AUTOSAR XML (schema 4-3-0)
package /MICROSAR/NvM_swc/DataTypes
  impl type NvM_BlockIdType: range raw 1..32767, implementation-data-type=uint16
  impl type NvM_RequestResultType: compu {0=NVM_REQ_OK, 1=NVM_REQ_NOT_OK, 2=NVM_REQ_PENDING, 3=NVM_REQ_INTEGRITY_FAILED, 4=NVM_REQ_BLOCK_SKIPPED, 5=NVM_REQ_NV_INVALIDATED, 6=NVM_REQ_CANCELED, 7=NVM_REQ_REDUNDANCY_FAILED, 8=NVM_REQ_RESTORED_FROM_ROM}, range raw 0..8, implementation-data-type=uint8
package /MICROSAR/NvM_swc/Interfaces
  4 x client server interface, all with is-service=true, service-kind=NON-VOLATILE-RAM-MANAGER:
    NvMAdministration
      operation SetBlockProtection: possible-error=NvMAdministration/E_NOT_OK
        arg ProtectionEnabled: type=boolean, direction=IN
      error E_NOT_OK: error-code=1
    NvMService_AC3_SRBS
      6 x operation, all with possible-error=NvMService_AC3_SRBS/E_NOT_OK:
        GetErrorStatus
          arg ErrorStatus: type=NvM_RequestResultType, direction=OUT
        SetRamBlockStatus
          arg RamBlockStatus: type=boolean, direction=IN
        ReadBlock
          arg DstPtr: type=dtRef_VOID, direction=IN
        WriteBlock
          arg SrcPtr: type=dtRef_const_VOID, direction=IN
        InvalidateNvBlock
        EraseBlock
      error E_NOT_OK: error-code=1
    NvMService_AC3_SRBS_Defs
      7 x operation, all with possible-error=NvMService_AC3_SRBS_Defs/E_NOT_OK:
        GetErrorStatus
          arg ErrorStatus: type=NvM_RequestResultType, direction=OUT
        SetRamBlockStatus
          arg RamBlockStatus: type=boolean, direction=IN
        ReadBlock
          arg DstPtr: type=dtRef_VOID, direction=IN
        WriteBlock
          arg SrcPtr: type=dtRef_const_VOID, direction=IN
        RestoreBlockDefaults
          arg DstPtr: type=dtRef_VOID, direction=IN
        InvalidateNvBlock
        EraseBlock
      error E_NOT_OK: error-code=1
    NvMNotifyInitBlock
      operation InitBlock
package /MICROSAR/NvM_swc/ComponentTypes
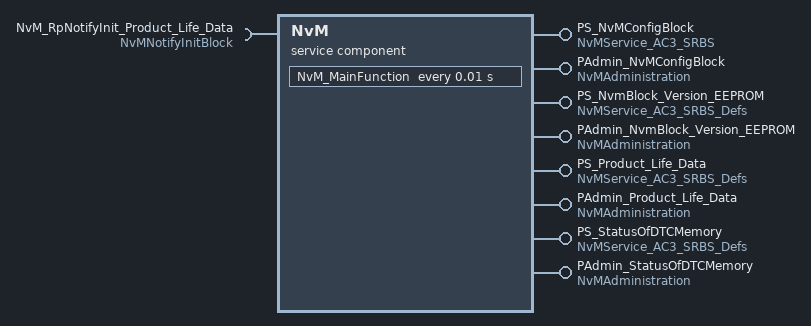
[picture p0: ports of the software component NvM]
  service sw component type NvM: category=SERVICE_COMPONENT
    6 x provide port:
      PS_NvMConfigBlock: provided-interface=NvMService_AC3_SRBS
      PAdmin_NvMConfigBlock: provided-interface=NvMAdministration
      PS_NvmBlock_Version_EEPROM: provided-interface=NvMService_AC3_SRBS_Defs
      PAdmin_NvmBlock_Version_EEPROM: provided-interface=NvMAdministration
      PS_Product_Life_Data: provided-interface=NvMService_AC3_SRBS_Defs
      PAdmin_Product_Life_Data: provided-interface=NvMAdministration
    require port NvM_RpNotifyInit_Product_Life_Data: required-interface=NvMNotifyInitBlock
    provide port PS_StatusOfDTCMemory: provided-interface=NvMService_AC3_SRBS_Defs
    provide port PAdmin_StatusOfDTCMemory: provided-interface=NvMAdministration
    behavior NvMInternalBehavior: handle-termination-and-restart=NO-SUPPORT
      timing event Timer_NvM_MainFunction: start-on-event=NvM_MainFunction, period=0.01
      31 x operation invoked event:
        OpEventGetErrorStatus_GetErrorStatus_PS_NvMConfigBlock: start-on-event=GetErrorStatus, operation=PS_NvMConfigBlock.GetErrorStatus
        OpEventGetErrorStatus_GetErrorStatus_PS_NvmBlock_Version_EEPROM: start-on-event=GetErrorStatus, operation=PS_NvmBlock_Version_EEPROM.GetErrorStatus
        OpEventGetErrorStatus_GetErrorStatus_PS_Product_Life_Data: start-on-event=GetErrorStatus, operation=PS_Product_Life_Data.GetErrorStatus
        OpEventGetErrorStatus_GetErrorStatus_PS_StatusOfDTCMemory: start-on-event=GetErrorStatus, operation=PS_StatusOfDTCMemory.GetErrorStatus
        OpEventSetRamBlockStatus_SetRamBlockStatus_PS_NvMConfigBlock: start-on-event=SetRamBlockStatus, operation=PS_NvMConfigBlock.SetRamBlockStatus
        OpEventSetRamBlockStatus_SetRamBlockStatus_PS_NvmBlock_Version_EEPROM: start-on-event=SetRamBlockStatus, operation=PS_NvmBlock_Version_EEPROM.SetRamBlockStatus
        OpEventSetRamBlockStatus_SetRamBlockStatus_PS_Product_Life_Data: start-on-event=SetRamBlockStatus, operation=PS_Product_Life_Data.SetRamBlockStatus
        OpEventSetRamBlockStatus_SetRamBlockStatus_PS_StatusOfDTCMemory: start-on-event=SetRamBlockStatus, operation=PS_StatusOfDTCMemory.SetRamBlockStatus
        OpEventReadBlock_ReadBlock_PS_NvMConfigBlock: start-on-event=ReadBlock, operation=PS_NvMConfigBlock.ReadBlock
        OpEventReadBlock_ReadBlock_PS_NvmBlock_Version_EEPROM: start-on-event=ReadBlock, operation=PS_NvmBlock_Version_EEPROM.ReadBlock
        OpEventReadBlock_ReadBlock_PS_Product_Life_Data: start-on-event=ReadBlock, operation=PS_Product_Life_Data.ReadBlock
        OpEventReadBlock_ReadBlock_PS_StatusOfDTCMemory: start-on-event=ReadBlock, operation=PS_StatusOfDTCMemory.ReadBlock
        OpEventWriteBlock_WriteBlock_PS_NvMConfigBlock: start-on-event=WriteBlock, operation=PS_NvMConfigBlock.WriteBlock
        OpEventWriteBlock_WriteBlock_PS_NvmBlock_Version_EEPROM: start-on-event=WriteBlock, operation=PS_NvmBlock_Version_EEPROM.WriteBlock
        OpEventWriteBlock_WriteBlock_PS_Product_Life_Data: start-on-event=WriteBlock, operation=PS_Product_Life_Data.WriteBlock
        OpEventWriteBlock_WriteBlock_PS_StatusOfDTCMemory: start-on-event=WriteBlock, operation=PS_StatusOfDTCMemory.WriteBlock
        OpEventInvalidateNvBlock_InvalidateNvBlock_PS_NvMConfigBlock: start-on-event=InvalidateNvBlock, operation=PS_NvMConfigBlock.InvalidateNvBlock
        OpEventInvalidateNvBlock_InvalidateNvBlock_PS_NvmBlock_Version_EEPROM: start-on-event=InvalidateNvBlock, operation=PS_NvmBlock_Version_EEPROM.InvalidateNvBlock
        OpEventInvalidateNvBlock_InvalidateNvBlock_PS_Product_Life_Data: start-on-event=InvalidateNvBlock, operation=PS_Product_Life_Data.InvalidateNvBlock
        OpEventInvalidateNvBlock_InvalidateNvBlock_PS_StatusOfDTCMemory: start-on-event=InvalidateNvBlock, operation=PS_StatusOfDTCMemory.InvalidateNvBlock
        OpEventEraseBlock_EraseBlock_PS_NvMConfigBlock: start-on-event=EraseBlock, operation=PS_NvMConfigBlock.EraseBlock
        OpEventEraseBlock_EraseBlock_PS_NvmBlock_Version_EEPROM: start-on-event=EraseBlock, operation=PS_NvmBlock_Version_EEPROM.EraseBlock
        OpEventEraseBlock_EraseBlock_PS_Product_Life_Data: start-on-event=EraseBlock, operation=PS_Product_Life_Data.EraseBlock
        OpEventEraseBlock_EraseBlock_PS_StatusOfDTCMemory: start-on-event=EraseBlock, operation=PS_StatusOfDTCMemory.EraseBlock
        OpEventSetBlockProtection_SetBlockProtection_PAdmin_NvMConfigBlock: start-on-event=SetBlockProtection, operation=PAdmin_NvMConfigBlock.SetBlockProtection
        OpEventSetBlockProtection_SetBlockProtection_PAdmin_NvmBlock_Version_EEPROM: start-on-event=SetBlockProtection, operation=PAdmin_NvmBlock_Version_EEPROM.SetBlockProtection
        OpEventSetBlockProtection_SetBlockProtection_PAdmin_Product_Life_Data: start-on-event=SetBlockProtection, operation=PAdmin_Product_Life_Data.SetBlockProtection
        OpEventSetBlockProtection_SetBlockProtection_PAdmin_StatusOfDTCMemory: start-on-event=SetBlockProtection, operation=PAdmin_StatusOfDTCMemory.SetBlockProtection
        OpEventRestoreBlockDefaults_RestoreBlockDefaults_PS_NvmBlock_Version_EEPROM: start-on-event=RestoreBlockDefaults, operation=PS_NvmBlock_Version_EEPROM.RestoreBlockDefaults
        OpEventRestoreBlockDefaults_RestoreBlockDefaults_PS_Product_Life_Data: start-on-event=RestoreBlockDefaults, operation=PS_Product_Life_Data.RestoreBlockDefaults
        OpEventRestoreBlockDefaults_RestoreBlockDefaults_PS_StatusOfDTCMemory: start-on-event=RestoreBlockDefaults, operation=PS_StatusOfDTCMemory.RestoreBlockDefaults
      port-api-options:
        {enable-take-address=true, indirect-api=false, port-defined-argument-value{value=1, value-type=NvM_BlockIdType}, port=PS_NvMConfigBlock}
        {enable-take-address=true, indirect-api=false, port-defined-argument-value{value=1, value-type=NvM_BlockIdType}, port=PAdmin_NvMConfigBlock}
        {enable-take-address=true, indirect-api=false, port-defined-argument-value{value=5, value-type=NvM_BlockIdType}, port=PS_NvmBlock_Version_EEPROM}
        {enable-take-address=true, indirect-api=false, port-defined-argument-value{value=5, value-type=NvM_BlockIdType}, port=PAdmin_NvmBlock_Version_EEPROM}
        {enable-take-address=true, indirect-api=false, port-defined-argument-value{value=4, value-type=NvM_BlockIdType}, port=PS_Product_Life_Data}
        {enable-take-address=true, indirect-api=false, port-defined-argument-value{value=4, value-type=NvM_BlockIdType}, port=PAdmin_Product_Life_Data}
        enable-take-address=true, indirect-api=false, port=NvM_RpNotifyInit_Product_Life_Data
        {enable-take-address=true, indirect-api=false, port-defined-argument-value{value=3, value-type=NvM_BlockIdType}, port=PS_StatusOfDTCMemory}
        {enable-take-address=true, indirect-api=false, port-defined-argument-value{value=3, value-type=NvM_BlockIdType}, port=PAdmin_StatusOfDTCMemory}
      9 x runnable:
        NvM_MainFunction
          sync call OpServerCallNvM_MainFunction_InitBlock_NvM_RpNotifyInit_Product_Life_Data: operation=NvM_RpNotifyInit_Product_Life_Data.InitBlock, timeout=0
        GetErrorStatus: can-be-invoked-concurrently=true, symbol=NvM_GetErrorStatus
        SetRamBlockStatus: can-be-invoked-concurrently=true, symbol=NvM_SetRamBlockStatus
        ReadBlock: can-be-invoked-concurrently=true, symbol=NvM_ReadBlock
        WriteBlock: can-be-invoked-concurrently=true, symbol=NvM_WriteBlock
        InvalidateNvBlock: can-be-invoked-concurrently=true, symbol=NvM_InvalidateNvBlock
        EraseBlock: can-be-invoked-concurrently=true, symbol=NvM_EraseNvBlock
        SetBlockProtection: can-be-invoked-concurrently=true, symbol=NvM_SetBlockProtection
        RestoreBlockDefaults: can-be-invoked-concurrently=true, symbol=NvM_RestoreBlockDefaults
  swc implementation NvMImplementation: programming-language=C, behavior=NvMInternalBehavior
